# ioam3358 register map
Registers are 32-bit, access not given, no defined reset value unless marked. A register's access mark holds for its fields unless they carry their own. Addresses are absolute; registers are grouped by the start of their names; [hi:lo] are bit positions; {n}, {i} and the like mark numbered series; 'fields as' and 'values as' point back to an identical list.

## USBSS
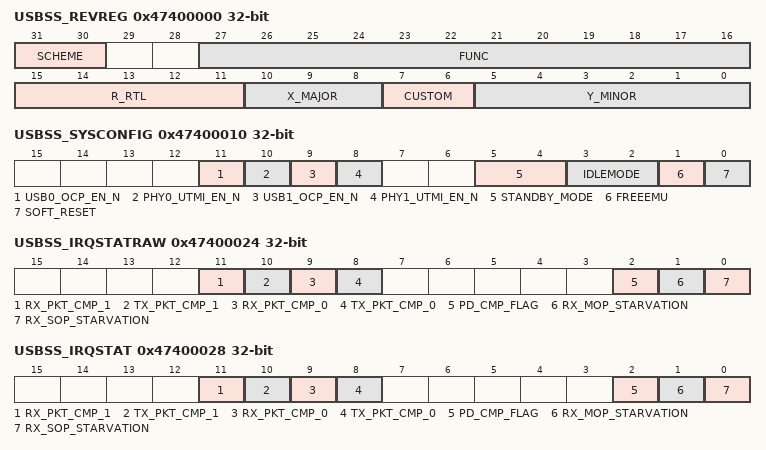
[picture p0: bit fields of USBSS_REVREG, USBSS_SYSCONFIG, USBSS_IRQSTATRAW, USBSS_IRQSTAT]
0x47400000 USBSS_REVREG
  [31:30] SCHEME, [27:16] FUNC, [15:11] R_RTL, [10:8] X_MAJOR, [7:6] CUSTOM, [5:0] Y_MINOR
0x47400010 USBSS_SYSCONFIG
  [11] USB0_OCP_EN_N, [10] PHY0_UTMI_EN_N, [9] USB1_OCP_EN_N, [8] PHY1_UTMI_EN_N, [5:4] STANDBY_MODE, [3:2] IDLEMODE, [1] FREEEMU, [0] SOFT_RESET
0x47400020 USBSS_EOI
  [0] EOI_VECTOR
0x47400024 USBSS_IRQSTATRAW
  [11] RX_PKT_CMP_1, [10] TX_PKT_CMP_1, [9] RX_PKT_CMP_0, [8] TX_PKT_CMP_0, [2] PD_CMP_FLAG, [1] RX_MOP_STARVATION, [0] RX_SOP_STARVATION
0x47400028 USBSS_IRQSTAT
  fields as USBSS_IRQSTATRAW
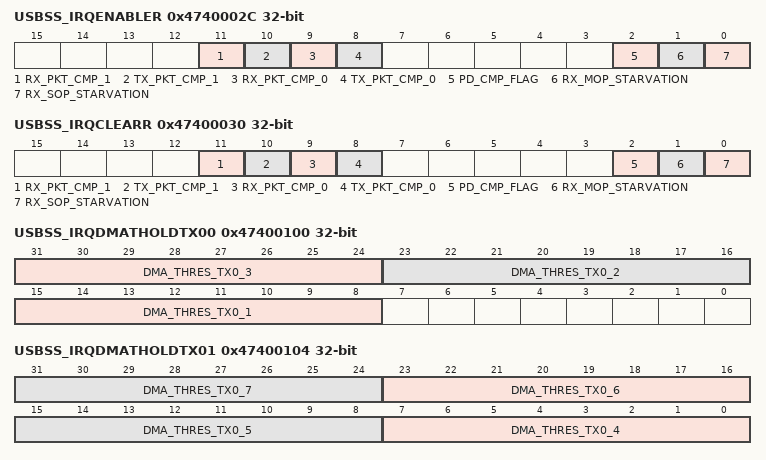
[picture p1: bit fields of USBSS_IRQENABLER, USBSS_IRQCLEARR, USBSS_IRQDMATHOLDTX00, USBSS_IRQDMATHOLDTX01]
0x4740002C USBSS_IRQENABLER
  fields as USBSS_IRQSTATRAW
0x47400030 USBSS_IRQCLEARR
  fields as USBSS_IRQSTATRAW
0x47400100 USBSS_IRQDMATHOLDTX00
  [31:24] DMA_THRES_TX0_3, [23:16] DMA_THRES_TX0_2, [15:8] DMA_THRES_TX0_1
0x47400104 USBSS_IRQDMATHOLDTX01
  [8n-25:8n-32] DMA_THRES_TX0_{n} (n=4..7)
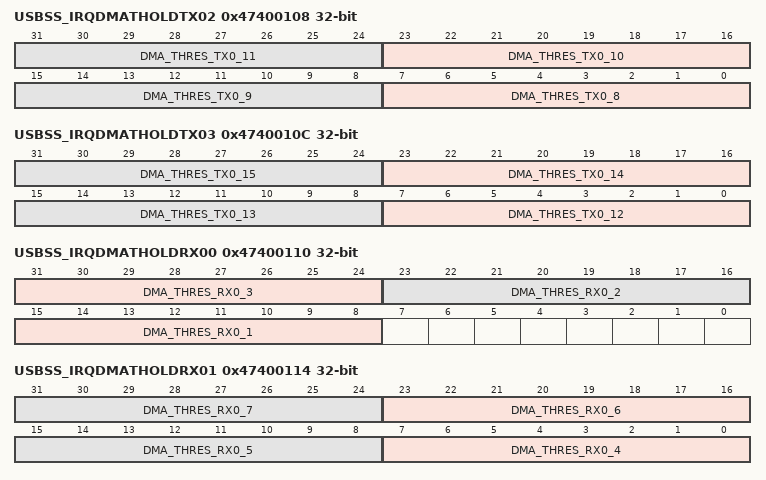
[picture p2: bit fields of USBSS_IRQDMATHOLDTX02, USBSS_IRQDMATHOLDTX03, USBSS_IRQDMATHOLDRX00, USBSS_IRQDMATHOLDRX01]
0x47400108 USBSS_IRQDMATHOLDTX02
  [8n-57:8n-64] DMA_THRES_TX0_{n} (n=8..11)
0x4740010C USBSS_IRQDMATHOLDTX03
  [8n-89:8n-96] DMA_THRES_TX0_{n} (n=12..15)
0x47400110 USBSS_IRQDMATHOLDRX00
  [31:24] DMA_THRES_RX0_3, [23:16] DMA_THRES_RX0_2, [15:8] DMA_THRES_RX0_1
0x47400114 USBSS_IRQDMATHOLDRX01
  [8n-25:8n-32] DMA_THRES_RX0_{n} (n=4..7)
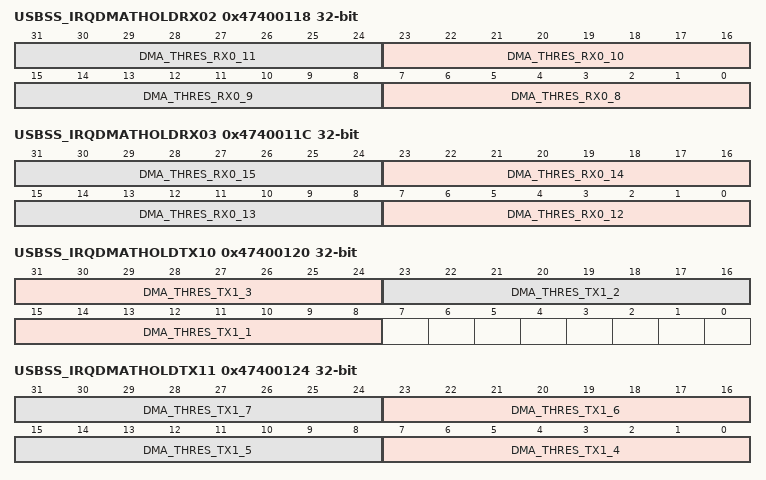
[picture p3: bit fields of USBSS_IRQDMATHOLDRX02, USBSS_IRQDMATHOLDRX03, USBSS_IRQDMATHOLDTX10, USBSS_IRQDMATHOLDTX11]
0x47400118 USBSS_IRQDMATHOLDRX02
  [8n-57:8n-64] DMA_THRES_RX0_{n} (n=8..11)
0x4740011C USBSS_IRQDMATHOLDRX03
  [8n-89:8n-96] DMA_THRES_RX0_{n} (n=12..15)
0x47400120 USBSS_IRQDMATHOLDTX10
  [31:24] DMA_THRES_TX1_3, [23:16] DMA_THRES_TX1_2, [15:8] DMA_THRES_TX1_1
0x47400124 USBSS_IRQDMATHOLDTX11
  [8n-25:8n-32] DMA_THRES_TX1_{n} (n=4..7)
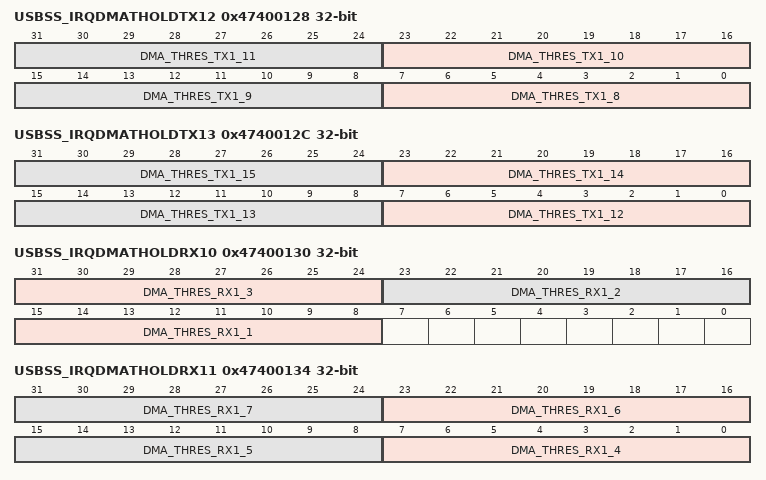
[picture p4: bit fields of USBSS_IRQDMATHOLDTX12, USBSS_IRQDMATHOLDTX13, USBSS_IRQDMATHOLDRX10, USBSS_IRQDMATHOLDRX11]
0x47400128 USBSS_IRQDMATHOLDTX12
  [8n-57:8n-64] DMA_THRES_TX1_{n} (n=8..11)
0x4740012C USBSS_IRQDMATHOLDTX13
  [8n-89:8n-96] DMA_THRES_TX1_{n} (n=12..15)
0x47400130 USBSS_IRQDMATHOLDRX10
  [31:24] DMA_THRES_RX1_3, [23:16] DMA_THRES_RX1_2, [15:8] DMA_THRES_RX1_1
0x47400134 USBSS_IRQDMATHOLDRX11
  [8n-25:8n-32] DMA_THRES_RX1_{n} (n=4..7)
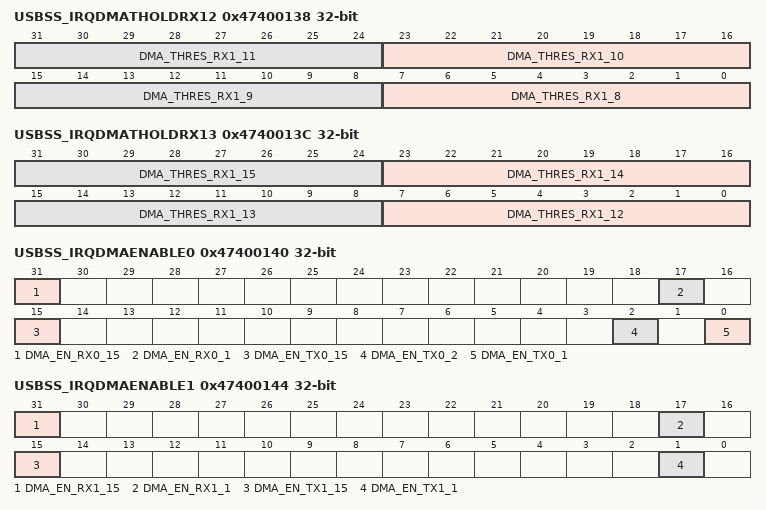
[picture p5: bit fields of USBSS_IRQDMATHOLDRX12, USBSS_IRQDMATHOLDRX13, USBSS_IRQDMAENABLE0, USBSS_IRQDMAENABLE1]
0x47400138 USBSS_IRQDMATHOLDRX12
  [8n-57:8n-64] DMA_THRES_RX1_{n} (n=8..11)
0x4740013C USBSS_IRQDMATHOLDRX13
  [8n-89:8n-96] DMA_THRES_RX1_{n} (n=12..15)
0x47400140 USBSS_IRQDMAENABLE0
  [31] DMA_EN_RX0_15, [17] DMA_EN_RX0_1, [15] DMA_EN_TX0_15, [2] DMA_EN_TX0_2, [0] DMA_EN_TX0_1
0x47400144 USBSS_IRQDMAENABLE1
  [31] DMA_EN_RX1_15, [17] DMA_EN_RX1_1, [15] DMA_EN_TX1_15, [1] DMA_EN_TX1_1
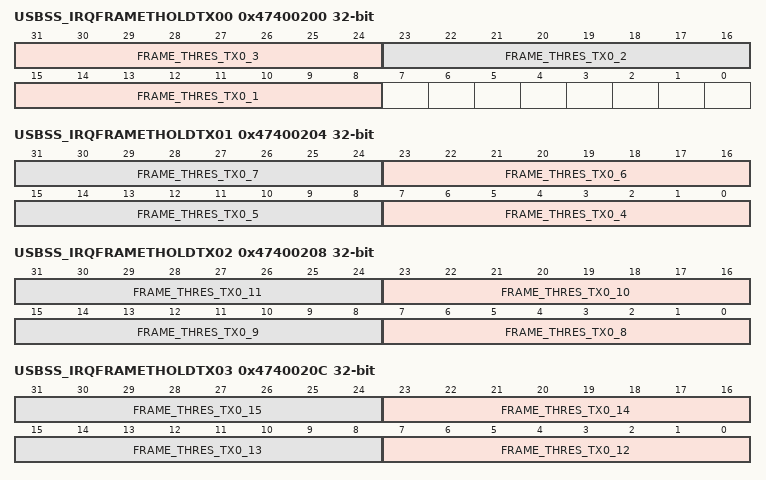
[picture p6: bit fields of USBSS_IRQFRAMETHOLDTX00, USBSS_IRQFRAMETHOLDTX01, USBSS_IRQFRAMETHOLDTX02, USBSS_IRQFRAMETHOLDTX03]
0x47400200 USBSS_IRQFRAMETHOLDTX00
  [31:24] FRAME_THRES_TX0_3, [23:16] FRAME_THRES_TX0_2, [15:8] FRAME_THRES_TX0_1
0x47400204 USBSS_IRQFRAMETHOLDTX01
  [8n-25:8n-32] FRAME_THRES_TX0_{n} (n=4..7)
0x47400208 USBSS_IRQFRAMETHOLDTX02
  [8n-57:8n-64] FRAME_THRES_TX0_{n} (n=8..11)
0x4740020C USBSS_IRQFRAMETHOLDTX03
  [8n-89:8n-96] FRAME_THRES_TX0_{n} (n=12..15)
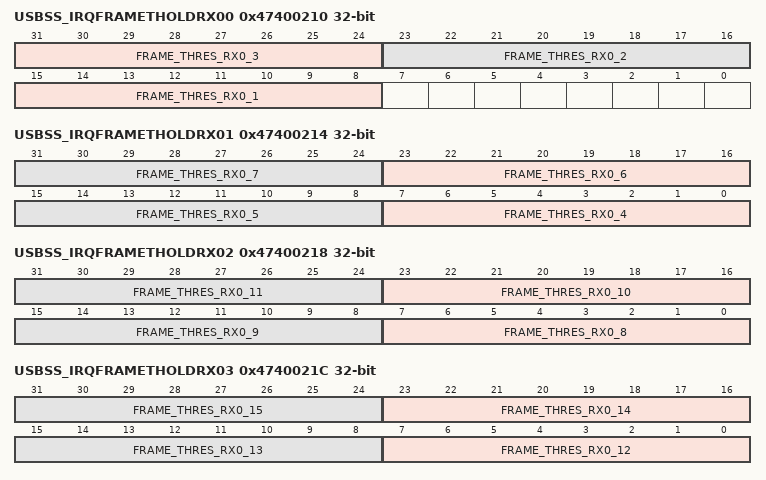
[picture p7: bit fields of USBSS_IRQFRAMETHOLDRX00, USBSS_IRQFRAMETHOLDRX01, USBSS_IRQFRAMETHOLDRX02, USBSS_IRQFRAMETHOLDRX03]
0x47400210 USBSS_IRQFRAMETHOLDRX00
  [31:24] FRAME_THRES_RX0_3, [23:16] FRAME_THRES_RX0_2, [15:8] FRAME_THRES_RX0_1
0x47400214 USBSS_IRQFRAMETHOLDRX01
  [8n-25:8n-32] FRAME_THRES_RX0_{n} (n=4..7)
0x47400218 USBSS_IRQFRAMETHOLDRX02
  [8n-57:8n-64] FRAME_THRES_RX0_{n} (n=8..11)
0x4740021C USBSS_IRQFRAMETHOLDRX03
  [8n-89:8n-96] FRAME_THRES_RX0_{n} (n=12..15)
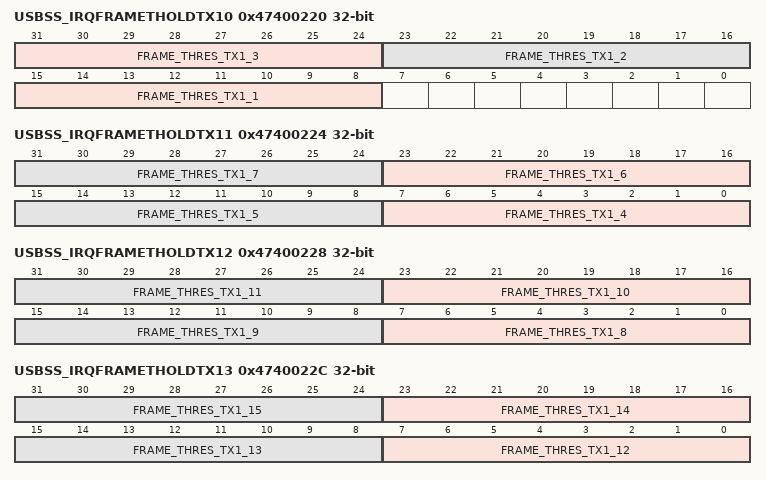
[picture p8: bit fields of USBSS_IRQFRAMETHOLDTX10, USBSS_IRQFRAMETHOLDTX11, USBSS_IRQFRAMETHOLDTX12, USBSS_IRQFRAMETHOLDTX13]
0x47400220 USBSS_IRQFRAMETHOLDTX10
  [31:24] FRAME_THRES_TX1_3, [23:16] FRAME_THRES_TX1_2, [15:8] FRAME_THRES_TX1_1
0x47400224 USBSS_IRQFRAMETHOLDTX11
  [8n-25:8n-32] FRAME_THRES_TX1_{n} (n=4..7)
0x47400228 USBSS_IRQFRAMETHOLDTX12
  [8n-57:8n-64] FRAME_THRES_TX1_{n} (n=8..11)
0x4740022C USBSS_IRQFRAMETHOLDTX13
  [8n-89:8n-96] FRAME_THRES_TX1_{n} (n=12..15)
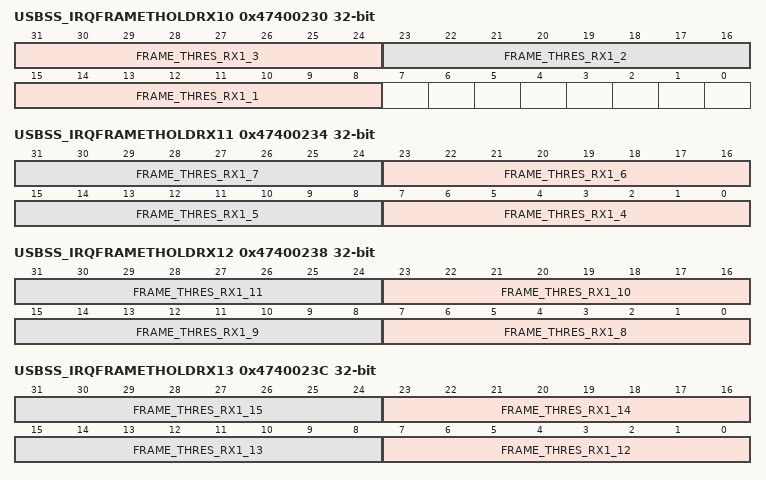
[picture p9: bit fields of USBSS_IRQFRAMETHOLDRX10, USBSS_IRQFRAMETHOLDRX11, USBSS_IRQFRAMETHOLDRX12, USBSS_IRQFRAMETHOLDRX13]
0x47400230 USBSS_IRQFRAMETHOLDRX10
  [31:24] FRAME_THRES_RX1_3, [23:16] FRAME_THRES_RX1_2, [15:8] FRAME_THRES_RX1_1
0x47400234 USBSS_IRQFRAMETHOLDRX11
  [8n-25:8n-32] FRAME_THRES_RX1_{n} (n=4..7)
0x47400238 USBSS_IRQFRAMETHOLDRX12
  [8n-57:8n-64] FRAME_THRES_RX1_{n} (n=8..11)
0x4740023C USBSS_IRQFRAMETHOLDRX13
  [8n-89:8n-96] FRAME_THRES_RX1_{n} (n=12..15)
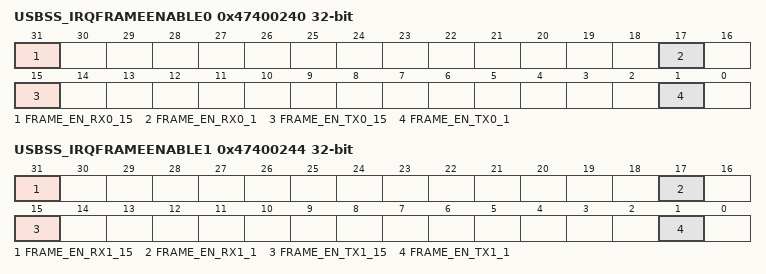
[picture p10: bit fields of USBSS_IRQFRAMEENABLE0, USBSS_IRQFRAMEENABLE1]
0x47400240 USBSS_IRQFRAMEENABLE0
  [31] FRAME_EN_RX0_15, [17] FRAME_EN_RX0_1, [15] FRAME_EN_TX0_15, [1] FRAME_EN_TX0_1
0x47400244 USBSS_IRQFRAMEENABLE1
  [31] FRAME_EN_RX1_15, [17] FRAME_EN_RX1_1, [15] FRAME_EN_TX1_15, [1] FRAME_EN_TX1_1
